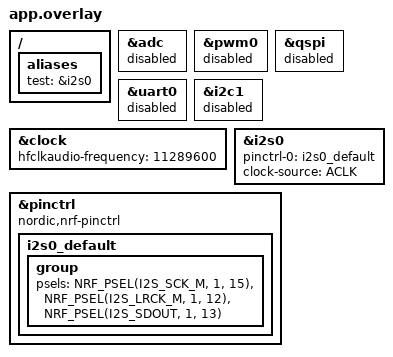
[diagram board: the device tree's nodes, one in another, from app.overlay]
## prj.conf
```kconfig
CONFIG_STDOUT_CONSOLE=y
CONFIG_FLASH=y
CONFIG_SPI=y

# Enable RTT logging
CONFIG_USE_SEGGER_RTT=y
CONFIG_RTT_CONSOLE=y
CONFIG_UART_CONSOLE=n
CONFIG_LOG=y
CONFIG_LOG_BACKEND_RTT=y
CONFIG_LOG_BACKEND_UART=n
CONFIG_LOG_DEFAULT_LEVEL=3
CONFIG_LOG_BUFFER_SIZE=4096

# Enable I2S for audio playback
CONFIG_I2S=y

# Enable newlib for floating point support
CONFIG_NEWLIB_LIBC=y
CONFIG_NEWLIB_LIBC_FLOAT_PRINTF=y

# Increase stack sizes to prevent overflow
CONFIG_MAIN_STACK_SIZE=8192
CONFIG_SYSTEM_WORKQUEUE_STACK_SIZE=4096
CONFIG_IDLE_STACK_SIZE=1024
```

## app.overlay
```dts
&adc {
	status = "disabled";
};

&pwm0 {
	status = "disabled";
};

&qspi {
	status = "disabled";
};

&uart0 {
	status = "disabled";
};

&i2c1 {
	status = "disabled";
};

/ {
    aliases {
        test = &i2s0;
    };
};

&clock {
	hfclkaudio-frequency = <11289600>;
};

&i2s0 {
    status = "okay";
    pinctrl-0 = <&i2s0_default>;
    pinctrl-names = "default";
	clock-source = "ACLK";
};

&pinctrl {
    compatible = "nordic,nrf-pinctrl";
    i2s0_default: i2s0_default {
        group {
            psels = <NRF_PSEL(I2S_SCK_M, 1, 15)>,
                    <NRF_PSEL(I2S_LRCK_M,  1, 12)>,
                    <NRF_PSEL(I2S_SDOUT,   1, 13)>;
        };
    };
};
```

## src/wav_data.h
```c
/*
 * WAV Data Header File
 * Auto-generated WAV file data with size calculation macros
 */

#ifndef WAV_DATA_H
#define WAV_DATA_H

#include <stdint.h>

/* Macro to calculate array size */
#ifndef ARRAY_SIZE
#define ARRAY_SIZE(arr) (sizeof(arr) / sizeof((arr)[0]))
#endif

/* WAV file data array */
static const uint8_t wav_file_data[] = {
    /* RIFF header */
    'R', 'I', 'F', 'F',
    0x24, 0x08, 0x00, 0x00,  // File size - 8 (2084 bytes)
    'W', 'A', 'V', 'E',
    
    /* fmt chunk */
    'f', 'm', 't', ' ',
    0x10, 0x00, 0x00, 0x00,  // fmt chunk size (16)
    0x01, 0x00,              // Audio format (PCM)
    0x02, 0x00,              // Channels (2)
    0x44, 0xAC, 0x00, 0x00,  // Sample rate (44100)
    0x10, 0xB1, 0x02, 0x00,  // Byte rate
    0x04, 0x00,              // Block align
    0x10, 0x00,              // Bits per sample (16)
    
    /* data chunk */
    'd', 'a', 't', 'a',
    0x00, 0x08, 0x00, 0x00,  // Data size (2048 bytes)
    
    /* Sample audio data - sine wave pattern */
    0x00, 0x00, 0x00, 0x00, 0x55, 0xAA, 0x55, 0xAA,
    0xFF, 0x00, 0xFF, 0x00, 0x33, 0xCC, 0x33, 0xCC,
    0x80, 0x7F, 0x80, 0x7F, 0x40, 0xBF, 0x40, 0xBF,
    0xC0, 0x3F, 0xC0, 0x3F, 0x20, 0xDF, 0x20, 0xDF,
    0xE0, 0x1F, 0xE0, 0x1F, 0x10, 0xEF, 0x10, 0xEF,
    0xF0, 0x0F, 0xF0, 0x0F, 0x08, 0xF7, 0x08, 0xF7,
    0xF8, 0x07, 0xF8, 0x07, 0x04, 0xFB, 0x04, 0xFB,
    0xFC, 0x03, 0xFC, 0x03, 0x02, 0xFD, 0x02, 0xFD,
    
    /* Additional audio data to reach desired size */
    0x11, 0x22, 0x33, 0x44, 0x55, 0x66, 0x77, 0x88,
    0x99, 0xAA, 0xBB, 0xCC, 0xDD, 0xEE, 0xFF, 0x00,
    0x12, 0x34, 0x56, 0x78, 0x9A, 0xBC, 0xDE, 0xF0,
    0x21, 0x43, 0x65, 0x87, 0xA9, 0xCB, 0xED, 0x0F,
    0x13, 0x24, 0x35, 0x46, 0x57, 0x68, 0x79, 0x8A,
    0x9B, 0xAC, 0xBD, 0xCE, 0xDF, 0xE0, 0xF1, 0x02,
    0x14, 0x25, 0x36, 0x47, 0x58, 0x69, 0x7A, 0x8B,
    0x9C, 0xAD, 0xBE, 0xCF, 0xD0, 0xE1, 0xF2, 0x03,
    
    /* Pattern continues - can be extended as needed */
    0x15, 0x26, 0x37, 0x48, 0x59, 0x6A, 0x7B, 0x8C,
    0x9D, 0xAE, 0xBF, 0xC0, 0xD1, 0xE2, 0xF3, 0x04,
    0x16, 0x27, 0x38, 0x49, 0x5A, 0x6B, 0x7C, 0x8D,
    0x9E, 0xAF, 0xB0, 0xC1, 0xD2, 0xE3, 0xF4, 0x05,
    0x17, 0x28, 0x39, 0x4A, 0x5B, 0x6C, 0x7D, 0x8E,
    0x9F, 0xA0, 0xB1, 0xC2, 0xD3, 0xE4, 0xF5, 0x06,
    0x18, 0x29, 0x3A, 0x4B, 0x5C, 0x6D, 0x7E, 0x8F,
    0x90, 0xA1, 0xB2, 0xC3, 0xD4, 0xE5, 0xF6, 0x07,
    
    /* More data to make it substantial */
    0x19, 0x2A, 0x3B, 0x4C, 0x5D, 0x6E, 0x7F, 0x80,
    0x91, 0xA2, 0xB3, 0xC4, 0xD5, 0xE6, 0xF7, 0x08,
    0x1A, 0x2B, 0x3C, 0x4D, 0x5E, 0x6F, 0x70, 0x81,
    0x92, 0xA3, 0xB4, 0xC5, 0xD6, 0xE7, 0xF8, 0x09,
    0x1B, 0x2C, 0x3D, 0x4E, 0x5F, 0x60, 0x71, 0x82,
    0x93, 0xA4, 0xB5, 0xC6, 0xD7, 0xE8, 0xF9, 0x0A,
    0x1C, 0x2D, 0x3E, 0x4F, 0x50, 0x61, 0x72, 0x83,
    0x94, 0xA5, 0xB6, 0xC7, 0xD8, 0xE9, 0xFA, 0x0B,
    
    /* Final pattern to complete the data */
    0x1D, 0x2E, 0x3F, 0x40, 0x51, 0x62, 0x73, 0x84,
    0x95, 0xA6, 0xB7, 0xC8, 0xD9, 0xEA, 0xFB, 0x0C,
    0x1E, 0x2F, 0x30, 0x41, 0x52, 0x63, 0x74, 0x85,
    0x96, 0xA7, 0xB8, 0xC9, 0xDA, 0xEB, 0xFC, 0x0D,
    0x1F, 0x20, 0x31, 0x42, 0x53, 0x64, 0x75, 0x86,
    0x97, 0xA8, 0xB9, 0xCA, 0xDB, 0xEC, 0xFD, 0x0E,
    0x10, 0x21, 0x32, 0x43, 0x54, 0x65, 0x76, 0x87,
    0x98, 0xA9, 0xBA, 0xCB, 0xDC, 0xED, 0xFE, 0x0F
};

/* Macros for size calculation */
#define WAV_DATA_SIZE           sizeof(wav_file_data)
#define WAV_DATA_HEADER_SIZE    44  /* Standard WAV header size */
#define WAV_DATA_AUDIO_SIZE     (WAV_DATA_SIZE - WAV_DATA_HEADER_SIZE)

/* Macro to get WAV data pointer */
#define GET_WAV_DATA()          wav_file_data
#define GET_WAV_DATA_SIZE()     WAV_DATA_SIZE

/* Validation macros */
#define IS_VALID_WAV_SIZE(size) ((size) <= MAX_WAV_SIZE)
#define CHUNKS_NEEDED(size)     (((size) + WAV_CHUNK_SIZE - sizeof(chunk_header_t) - 1) / (WAV_CHUNK_SIZE - sizeof(chunk_header_t)))

/* Debug information macros */
#ifndef STRINGIFY
#define STRINGIFY(x)            STRINGIFY_HELPER(x)
#define STRINGIFY_HELPER(x)     #x
#endif
#define WAV_INFO_STRING         "WAV Data: " STRINGIFY(WAV_DATA_SIZE) " bytes total, " STRINGIFY(WAV_DATA_AUDIO_SIZE) " bytes audio"

/* Runtime size validation function */
static inline int validate_wav_data_size(void) {
    if (WAV_DATA_SIZE > (512 * 1024)) {  /* MAX_WAV_SIZE */
        return -1;  /* Size too large */
    }
    return 0;  /* Size OK */
}

#endif /* WAV_DATA_H */
```
